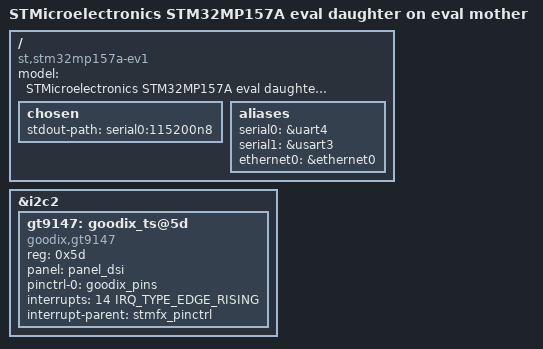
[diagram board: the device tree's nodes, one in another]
// SPDX-License-Identifier: (GPL-2.0+ OR BSD-3-Clause)
/*
 * Copyright (C) STMicroelectronics 2019 - All Rights Reserved
 * Author: Alexandre Torgue <alexandre.torgue@st.com> for STMicroelectronics.
 */
/dts-v1/;

#include "stm32mp157a-ed1.dts"
#include "stm32mp15xx-evx.dtsi"

/ {
	model = "STMicroelectronics STM32MP157A eval daughter on eval mother";
	compatible = "st,stm32mp157a-ev1", "st,stm32mp157a-ed1", "st,stm32mp157";

	chosen {
		stdout-path = "serial0:115200n8";
	};

	aliases {
		serial0 = &uart4;
		serial1 = &usart3;
		ethernet0 = &ethernet0;
	};
};

&i2c2 {
	gt9147: goodix_ts@5d {
		compatible = "goodix,gt9147";
		reg = <0x5d>;
		panel = <&panel_dsi>;
		pinctrl-0 = <&goodix_pins>;
		pinctrl-names = "default";
		status = "okay";

		interrupts = <14 IRQ_TYPE_EDGE_RISING>;
		interrupt-parent = <&stmfx_pinctrl>;
	};
};
